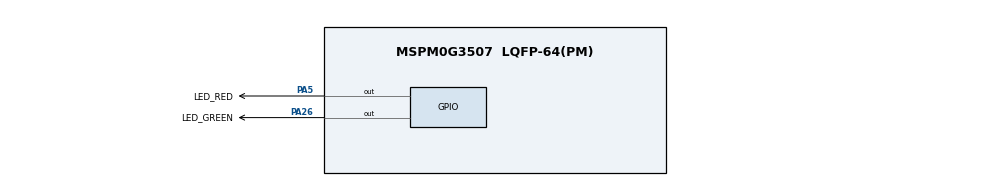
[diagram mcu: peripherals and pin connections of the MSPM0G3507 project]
/** TI machine-horse LED introduction. RGB: R=PA5, G=PA26, B=PA6; active low. */
//@cliArgs --device "MSPM0G350X" --package "LQFP-64(PM)" --part "Default"
//@v2CliArgs --device "MSPM0G3507" --package "LQFP-64(PM)"
const GPIO = scripting.addModule("/ti/driverlib/GPIO", {}, false);
const GPIO1 = GPIO.addInstance();
const SYSCTL = scripting.addModule("/ti/driverlib/SYSCTL");
const Board = scripting.addModule("/ti/driverlib/Board", {}, false);
GPIO1.$name = "GPIO_LEDS";
GPIO1.port = "PORTA";
GPIO1.associatedPins.create(2);
GPIO1.associatedPins[0].$name = "LED_GREEN";
GPIO1.associatedPins[0].assignedPin = "26";
GPIO1.associatedPins[0].pin.$assign = "PA26";
GPIO1.associatedPins[0].direction = "OUTPUT";
GPIO1.associatedPins[0].initialValue = "SET";
/* The red channel stays off; add LED_BLUE on PA6 yourself in SysConfig. */
GPIO1.associatedPins[1].$name = "LED_RED";
GPIO1.associatedPins[1].assignedPin = "5";
GPIO1.associatedPins[1].pin.$assign = "PA5";
GPIO1.associatedPins[1].direction = "OUTPUT";
GPIO1.associatedPins[1].initialValue = "SET";
SYSCTL.forceDefaultClkConfig = true;
SYSCTL.clockTreeEn = true;
